# GPMC register map
Vendor: Texas Instruments
Peripheral module from a debugger description file (folder am437x).
Registers are 32-bit, access not given, no defined reset value unless marked. A register's access mark holds for its fields unless they carry their own. Offsets are as the file gives them; lines under a group give offsets from that group; [hi:lo] are bit positions; {n}, {i} and the like mark numbered series; 'fields as' and 'values as' point back to an identical list; <NAME> marks a mode.

## GPMC
0x00 GPMC_REVISION ro — The GPMC_REVISION register contains the IP revision code.
  [7:0] REV — IP revision. [[br]]Major revision is [[br]][7:4]. [[br]]Minor revision is [[br]][3:0]. [[br]]Examples: 10h for revision 1.0, 21h for revision 2.1.
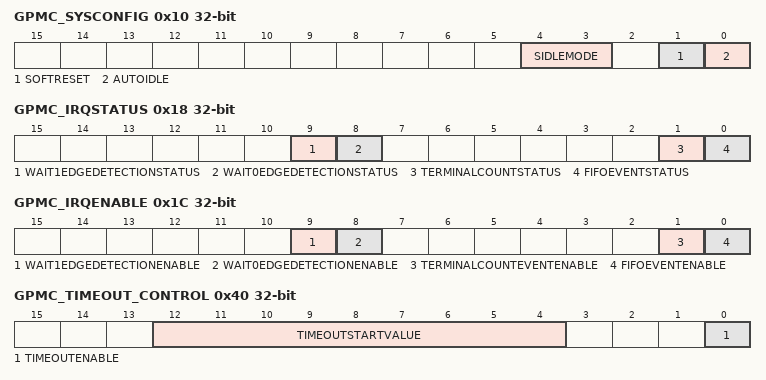
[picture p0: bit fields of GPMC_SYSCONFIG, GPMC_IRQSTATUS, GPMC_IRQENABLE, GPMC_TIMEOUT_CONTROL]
0x10 GPMC_SYSCONFIG access per field — The GPMC_SYSCONFIG register controls the various parameters of the OCP interface.
  [4:3] SIDLEMODE rw — Idle mode
    3=en_4_0x3 (Reserved); 2=en_3_0x2 (Smart-idle. Acknowledgment to an idle request is given based on the internal activity of the module); 1=en_2_0x1 (No-idle. An idle request is never acknowledged); 0=en_1_0x0 (Force-idle. An idle request is acknowledged unconditionally)
  [1] SOFTRESET rw — Software reset (Set 1 to this bit triggers a module reset. [[br]]This bit is automatically reset by hardware. [[br]]During reads, it always returns 0).
    1=en_2_0x1 (The module is reset); 0=en_1_0x0 (Normal mode)
  [0] AUTOIDLE rw — Internal OCP clock gating strategy.
    1=en_2_0x1 (Automatic interface clock gating strategy is applied based on the Interconnect activity.); 0=en_1_0x0 (Interface clock is free-running)
0x14 GPMC_SYSSTATUS ro — The GPMC_SYSSTATUS register provides status information about the module, excluding the interrupt status information.
  [0] RESETDONE — Internal reset monitoring
    1=en_2_0x1 (Reset completed); 0=en_1_0x0 (Internal module reset in on-going)
0x18 GPMC_IRQSTATUS access per field — The GPMC_IRQSTATUS interrupt status register regroups all the status of the module internal events that can generate an interrupt.
  [9] WAIT1EDGEDETECTIONSTATUS rw — Status of the Wait1 Edge Detection interrupt
    1=en_4_0x1 (WAIT1EDGEDETECTIONSTATUS bit is reset); 1=en_3_0x1 (A transition on WAIT1 input pin has been detected); 0=en_2_0x0 (WAIT1EDGEDETECTIONSTATUS bit unchanged); 0=en_1_0x0 (A transition on WAIT1 input pin has not been detected)
  [8] WAIT0EDGEDETECTIONSTATUS rw — Status of the Wait0 Edge Detection interrupt
    1=en_4_0x1 (WAIT0EDGEDETECTIONSTATUS bit is reset); 1=en_3_0x1 (A transition on WAIT0 input pin has been detected); 0=en_2_0x0 (A transition on WAIT0 input pin has not been detected); 0=en_1_0x0 (WAIT0EDGEDETECTIONSTATUS bit unchanged)
  [1] TERMINALCOUNTSTATUS rw — Status of the TerminalCountEvent interrupt
    1=en_2_0x1 (Indicates that CountValue is equal to 0); 0=en_1_0x0 (TERMINALCOUNTSTATUS bit unchanged)
  [0] FIFOEVENTSTATUS rw — Status of the FIFOEvent interrupt
    1=en_4_0x1 (FIFOEVENTSTATUS bit is reset); 1=en_3_0x1 (Indicates than at least GPMC_PREFETCH_STATUS[16] FIFOTHRESHOLDSTATUS bytes are available in prefetch mode and at least FIFOTHRESHOLD bytes free places are available in write-posting mode.); 0=en_2_0x0 (Indicates than less than GPMC_PREFETCH_STATUS[16] FIFOTHRESHOLDSTATUS bytes are available in prefetch mode and less than FIFOTHRESHOLD bytes free places are available in write-posting mode.); 0=en_1_0x0 (FIFOEVENTSTATUS bit unchanged)
0x1C GPMC_IRQENABLE access per field — The GPMC_IRQENABLE interrupt enable register allows to mask/unmask the module internal sources of interrupt, on a event-by-event basis.
  [9] WAIT1EDGEDETECTIONENABLE rw — Enables the Wait1 Edge Detection interrupt
    1=en_2_0x1 (Wait1EdgeDetection event generates an interrupt if occurs); 0=en_1_0x0 (Wait1EdgeDetection interrupt is masked)
  [8] WAIT0EDGEDETECTIONENABLE rw — Enables the Wait0 Edge Detection interrupt
    1=en_2_0x1 (Wait0EdgeDetection event generates an interrupt if occurs); 0=en_1_0x0 (Wait0EdgeDetection interrupt is masked)
  [1] TERMINALCOUNTEVENTENABLE rw — Enables TerminalCountEvent interrupt issuing in pre-fetch or write posting mode
    1=en_2_0x1 (TerminalCountEvent interrupt is not masked); 0=en_1_0x0 (TerminalCountEvent interrupt is masked)
  [0] FIFOEVENTENABLE rw — Enables the FIFOEvent interrupt
    1=en_2_0x1 (FIFOEvent interrupt is not masked); 0=en_1_0x0 (FIFOEvent interrupt is masked)
0x40 GPMC_TIMEOUT_CONTROL access per field — The GPMC_TIMEOUT_CONTROL register allows the user to set the start value of the timeout counter
  [12:4] TIMEOUTSTARTVALUE rw — Start value of the time-out counter (000 corresponds to 0 GPMC.FCLK cycle, 1h corresponds to 1 GPMC.FCLK cycle, and 1FFh corresponds to 511 GPMC.FCLK cycles)
  [0] TIMEOUTENABLE rw — Enable bit of the TimeOut feature
    1=en_2_0x1 (TimeOut feature is enabled); 0=en_1_0x0 (TimeOut feature is disabled)
0x44 GPMC_ERR_ADDRESS access per field — The GPMC_ERR_ADDRESS register stores the address of the illegal access when an error occurs.
  [30:0] ILLEGALADD rw — Address of illegal access: A30 (0 for memory region, 1 for GPMC register region) and A29 to A0 (1GByte maximum)
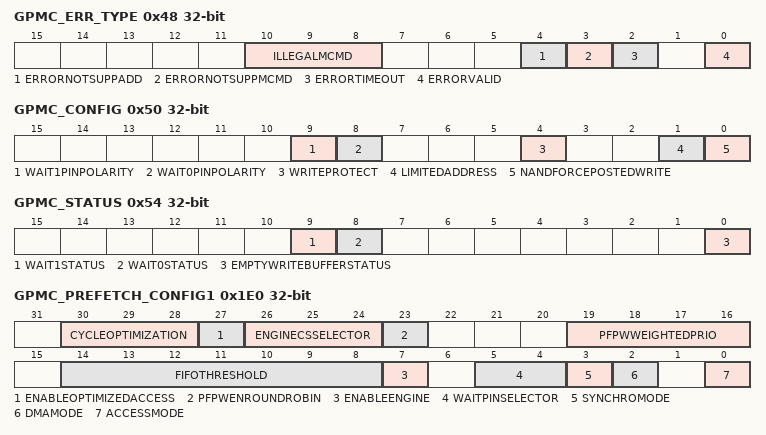
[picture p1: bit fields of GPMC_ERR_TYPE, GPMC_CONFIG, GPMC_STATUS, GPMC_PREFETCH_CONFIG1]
0x48 GPMC_ERR_TYPE access per field — The GPMC_ERR_TYPE register stores the type of error when an error occurs.
  [10:8] ILLEGALMCMD rw — System Command of the transaction that caused the error
  [4] ERRORNOTSUPPADD rw — Not supported Address error
    1=en_2_0x1 (The error is due to a non supported Address); 0=en_1_0x0 (No error occurs)
  [3] ERRORNOTSUPPMCMD rw — Not supported Command error
    1=en_2_0x1 (The error is due to a non supported Command); 0=en_1_0x0 (No error occurs)
  [2] ERRORTIMEOUT rw — Time-out error
    1=en_2_0x1 (The error is due to a time out); 0=en_1_0x0 (No error occurs)
  [0] ERRORVALID rw — Error validity status - Must be explicitly cleared with a write 1 transaction
    1=en_2_0x1 (Error detected and logged in the other error fields); 0=en_1_0x0 (All error fields no longer valid)
0x50 GPMC_CONFIG access per field — The configuration register allows global configuration of the GPMC.
  [9] WAIT1PINPOLARITY rw — Selects the polarity of input pin WAIT1.
    1=en_2_0x1 (WAIT1 active high); 0=en_1_0x0 (WAIT1 active low)
  [8] WAIT0PINPOLARITY rw — Selects the polarity of input pin WAIT0.
    1=en_2_0x1 (WAIT0 active high); 0=en_1_0x0 (WAIT0 active low)
  [4] WRITEPROTECT rw — Controls the WP output pin level.
    1=en_2_0x1 (WP output pin is high); 0=en_1_0x0 (WP output pin is low)
  [1] LIMITEDADDRESS rw — Limited Address device support.
    1=en_2_0x1 (A26-A11 are not modified during an external memory access.); 0=en_1_0x0 (No effect. GPMC controls all addresses.)
  [0] NANDFORCEPOSTEDWRITE rw
    1=en_2_0x1 (Enables Force Posted Write); 0=en_1_0x0 (Disables Force Posted Write)
0x54 GPMC_STATUS access per field — The status register provides global status bits of the GPMC.
  [9] WAIT1STATUS rw — Is a copy of input pin WAIT1. [[br]](Reset value is WAIT1 input pin sampled at IC reset)
    1=en_2_0x1 (WAIT1 de-asserted); 0=en_1_0x0 (WAIT1 asserted (inactive state))
  [8] WAIT0STATUS rw — Is a copy of input pin WAIT0. [[br]](Reset value is WAIT0 input pin sampled at IC reset)
    1=en_2_0x1 (WAIT0 de-asserted); 0=en_1_0x0 (WAIT0 asserted (inactive state))
  [0] EMPTYWRITEBUFFERSTATUS rw — Stores the empty status of the write buffer
    1=en_2_0x1 (Write Buffer is empty); 0=en_1_0x0 (Write Buffer is not empty)
{0x5C+4i} GPMC_CONFIG{i}_0 (i=1..7)
{0x7C+0x30*i} GPMC_NAND_COMMAND_{i} (i=0..6)
{0x80+0x30*i} GPMC_NAND_ADDRESS_{i} (i=0..6)
{0x84+0x30*i} GPMC_NAND_DATA_{i} (i=0..6)
{0x8C+4i} GPMC_CONFIG{i}_1 (i=1..7)
{0xBC+4i} GPMC_CONFIG{i}_2 (i=1..7)
{0xEC+4i} GPMC_CONFIG{i}_3 (i=1..7)
{0x11C+4i} GPMC_CONFIG{i}_4 (i=1..7)
{0x14C+4i} GPMC_CONFIG{i}_5 (i=1..7)
{0x17C+4i} GPMC_CONFIG{i}_6 (i=1..7)
0x1E0 GPMC_PREFETCH_CONFIG1 access per field
  [30:28] CYCLEOPTIMIZATION rw — Define the number of GPMC.FCLK cycles to be substracted from RdCycleTime, WrCycleTime, AccessTime, CSRdOffTime, CSWrOffTime, ADVRdOffTime, ADVWrOffTime, OEOffTime, WEOffTime
    7=en_3_0x7 (7 GPMC_FCLK cycles); 1=en_2_0x1 (1 GPMC_FCLK cycle); 0=en_1_0x0 (0 GPMC_FCLK cycle)
  [27] ENABLEOPTIMIZEDACCESS rw — Enables access cycle optimization
    1=en_2_0x1 (Access cycle optimization is enabled); 0=en_1_0x0 (Access cycle optimization is disabled)
  [26:24] ENGINECSSELECTOR rw — Selects the CS (active low) where Prefetch Postwrite engine is active
    {v}=en_{v+1}_{0x0+v} (CS{v} (active low)) (v=0..6)
  [23] PFPWENROUNDROBIN rw
  [19:16] PFPWWEIGHTEDPRIO rw
  [14:8] FIFOTHRESHOLD rw
  [7] ENABLEENGINE rw
  [5:4] WAITPINSELECTOR rw
  [3] SYNCHROMODE rw
  [2] DMAMODE rw
  [0] ACCESSMODE rw
0x1E4 GPMC_PREFETCH_CONFIG2 access per field
  [13:0] TRANSFERCOUNT rw — Selects the number of bytes to be read or written by the engine to the selected CS (active low)
    0x2000=en_3_0x2000 (8 Kbytes); 1=en_2_0x1 (1 byte); 0=en_1_0x0 (0 byte)
0x1EC GPMC_PREFETCH_CONTROL access per field
  [0] STARTENGINE rw — Resets the FIFO pointer and starts the engine
    1=en_4_0x1 (Resets the FIFO pointer to 0 in prefetch mode and 40h in postwrite mode and starts the engine); 1=en_3_0x1 (Engine is running); 0=en_2_0x0 (Stops the engine); 0=en_1_0x0 (Engine is stopped)
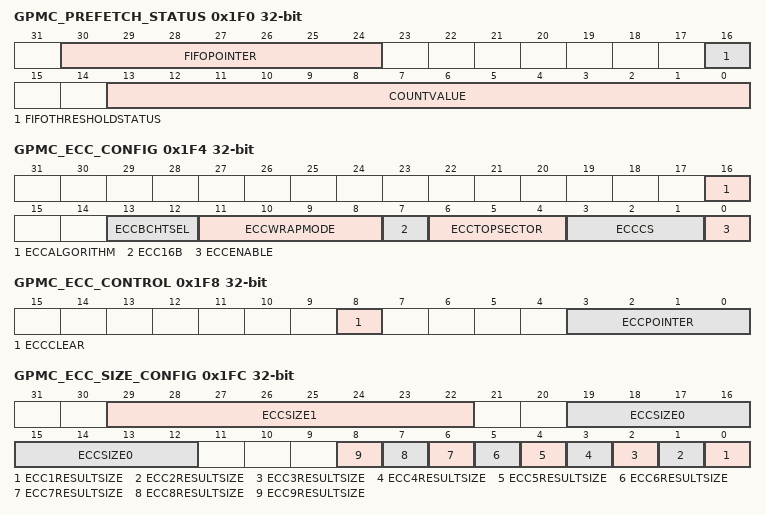
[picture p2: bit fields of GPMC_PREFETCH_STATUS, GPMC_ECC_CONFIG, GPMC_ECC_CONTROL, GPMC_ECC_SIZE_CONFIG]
0x1F0 GPMC_PREFETCH_STATUS ro
  [30:24] FIFOPOINTER
    64=en_2_0x40 (64 bytes available to be read or 64 empty places to be written); 0=en_1_0x0 (0 byte available to be read or 0 free empty place to be written)
  [16] FIFOTHRESHOLDSTATUS — Set when FIFOPointer exceeds FIFOThreshold value.
    1=en_2_0x1 (FIFOPointer greater than FIFOThreshold. Writing to this bit has no effect); 0=en_1_0x0 (FIFOPointer smaller or equal to FIFOThreshold. Writing to this bit has no effect)
  [13:0] COUNTVALUE — Number of remaining bytes to be read or to be written by the engine according to the TransferCount value.
    0x2000=en_3_0x2000 (8 Kbytes remaining to be read or to be written); 1=en_2_0x1 (1 byte remaining to be read or to be writte); 0=en_1_0x0 (0 byte remaining to be read or to be written)
0x1F4 GPMC_ECC_CONFIG access per field
  [16] ECCALGORITHM rw — ECC algorithm used
    1=en_2_0x1 (BCH code); 0=en_1_0x0 (Hamming code)
  [13:12] ECCBCHTSEL rw — Error correction capability used for BCH
    3=en_4_0x3 (Reserved); 2=en_3_0x2 (Up to 16 bits error correction (t = 16)); 1=en_2_0x1 (Up to 8 bits error correction (t = 8)); 0=en_1_0x0 (Up to 4 bits error correction (t = 4))
  [11:8] ECCWRAPMODE rw — Spare area organization definition for the BCH algorithm. [[br]]See the BCH syndrome/parity calculator module functional specification for more details
  [7] ECC16B rw — Selects an ECC calculated on 16 columns
    1=en_2_0x1 (ECC calculated on 16 columns); 0=en_1_0x0 (ECC calculated on 8 columns)
  [6:4] ECCTOPSECTOR rw — Number of sectors to process with the BCH algorithm
    7=en_4_0x7 (8 sectors (4kB page)); 3=en_3_0x3 (4 sectors (2kB page)); 1=en_2_0x1 (2 sectors); 0=en_1_0x0 (1 sector (512kB page))
  [3:1] ECCCS rw — Selects the Chip-select where ECC is computed
    7=en_8_0x7 (Reserved); 6=en_7_0x6 (Reserved); {v}=en_{v+1}_{0x0+v} (Chip-select {v}) (v=0..5)
  [0] ECCENABLE rw — Enables the ECC feature
    1=en_2_0x1 (ECC enabled); 0=en_1_0x0 (ECC disabled)
0x1F8 GPMC_ECC_CONTROL access per field
  [8] ECCCLEAR rw — Clear all ECC result registers
    1=en_3_0x1 (Clears all ECC result registers); 0=en_2_0x0 (Ignored); 0=en_1_0x0 (All reads return 0)
  [3:0] ECCPOINTER rw — Selects ECC result register (Reads to this field give the dynamic position of the ECC pointer - Writes to this field select the ECC result register where the first ECC computation will be stored). [[br]]Writing values not listed disables the ECC engine (ECCEnable bit of GPMC_ECC_CONFIG cleared to 0).
    {v}=en_{v+1}_{0x0+v} (ECC result register {v} selected) (v=1..9); 0=en_1_0x0 (Writing 0 disables the ECC engine (ECCENABLE bit of GPMC_ECC_CONFIG cleared to 0))
0x1FC GPMC_ECC_SIZE_CONFIG access per field
  [29:22] ECCSIZE1 rw — Defines ECC size 1
    255=en_5_0xFF (512 Bytes); 3=en_4_0x3 (8 Bytes); 2=en_3_0x2 (6 Bytes); 1=en_2_0x1 (4 Bytes); 0=en_1_0x0 (2 Bytes)
  [19:12] ECCSIZE0 rw — Defines ECC size 0
    values as ECCSIZE1
  [n-1] ECC{n}RESULTSIZE rw (n=1..9) — Selects ECC size for ECC {n} result register
    1=en_2_0x1 (ECCSIZE1 selected); 0=en_1_0x0 (ECCSIZE0 selected)
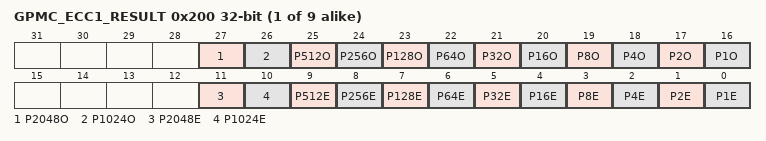
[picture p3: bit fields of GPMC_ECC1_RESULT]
{0x1FC+4i} GPMC_ECC{i}_RESULT ro (i=1..9)
  [27] P2048O — Odd Row Parity bit 2048, only used for ECC computed on 512 Bytes
  [26] P1024O — Odd Row Parity bit 1024
  [25] P512O — Odd Row Parity bit 512
  [24] P256O — Odd Row Parity bit 256
  [23] P128O — Odd Row Parity bit 128
  [22] P64O — Odd Row Parity bit 64
  [21] P32O — Odd Row Parity bit 32
  [20] P16O — Odd Row Parity bit 16
  [19] P8O — Odd Row Parity bit 8
  [18] P4O — Odd Column Parity bit 4
  [17] P2O — Odd Column Parity bit 2
  [16] P1O — Odd Column Parity bit 1
  [11] P2048E — Even Row Parity bit 2048, only used for ECC computed on 512 Bytes
  [10] P1024E — Even Row Parity bit 1024
  [9] P512E — Even Row Parity bit 512
  [8] P256E — Even Row Parity bit 256
  [7] P128E — Even Row Parity bit 128
  [6] P64E — Even Row Parity bit 64
  [5] P32E — Even Row Parity bit 32
  [4] P16E — Even Row Parity bit 16
  [3] P8E — Even Row Parity bit 8
  [2] P4E — Even Column Parity bit 4
  [1] P2E — Even Column Parity bit 2
  [0] P1E — Even Column Parity bit 1
{0x240+0x10*i} GPMC_BCH_RESULT0_{i} rw (i=0..6)
  [31:0] BCH_RESULT0_{i} — BCH ECC result, bits 0 to 31
{0x244+0x10*i} GPMC_BCH_RESULT1_{i} rw (i=0..6)
  [31:0] BCH_RESULT1_{i} — BCH ECC result, bits 32 to 63
{0x248+0x10*i} GPMC_BCH_RESULT2_{i} rw (i=0..6)
  [31:0] BCH_RESULT2_{i} — BCH ECC result, bits 64 to 95
{0x24C+0x10*i} GPMC_BCH_RESULT3_{i} rw (i=0..6)
  [31:0] BCH_RESULT3_{i} — BCH ECC result, bits 96 to 127
0x2D0 GPMC_BCH_SWDATA access per field — This register is used to directly pass data to the BCH ECC calculator without accessing the actual NAND flash interface.
  [15:0] BCH_DATA rw — Data to be included in the BCH calculation. [[br]]Only bits 0 to 7 are taken into account, if the calculator is configured to use 8 bits data (GPMC_ECC_CONFIG[7] ECC16B = 0).
{0x300+0x10*i} GPMC_BCH_RESULT4_{i} rw (i=0..6)
  [31:0] BCH_RESULT4_{i} — BCH ECC result, bits 128 to 159
{0x304+0x10*i} GPMC_BCH_RESULT5_{i} rw (i=0..6)
  [31:0] BCH_RESULT5_{i} — BCH ECC result, bits 160 to 191
{0x308+0x10*i} GPMC_BCH_RESULT6_{i} rw (i=0..6)
  [31:0] BCH_RESULT6_{i} — BCH ECC result, bits 192 to 207
